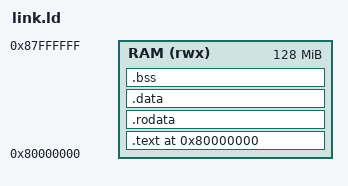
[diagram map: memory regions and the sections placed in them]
OUTPUT_ARCH(riscv)
ENTRY(_start)

MEMORY
{
    RAM (rwx) : ORIGIN = 0x80000000, LENGTH = 128M
}

SECTIONS
{
    . = ORIGIN(RAM);

    .text : ALIGN(4)
    {
        *(.text.init)
        *(.text*)
    } > RAM

    .rodata : ALIGN(4)
    {
        *(.rodata*)
    } > RAM

    .data : ALIGN(4)
    {
        *(.data*)
    } > RAM

    .bss : ALIGN(4)
    {
        __bss_start = .;
        *(.bss*)
        *(COMMON)
        __bss_end = .;
    } > RAM

    . = ALIGN(16);
    __stack_top = ORIGIN(RAM) + LENGTH(RAM);
}

